VERSION ""

NS_ :

BS_:

BU_: BMS VCU

BO_ 257 BMS_Faults: 8 BMS
 SG_ OverTemp : 1|1@1+ (1,0) [0.0|1.0] ""  VCU
 SG_ OverVoltage : 0|1@1+ (1,0) [0.0|1.0] ""  VCU

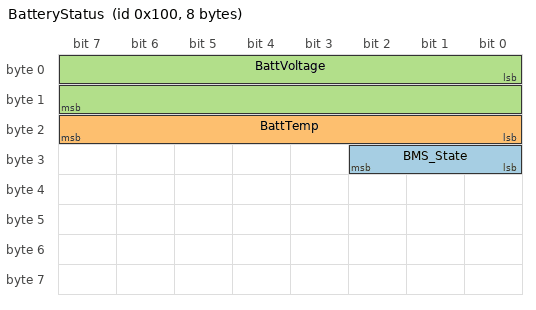
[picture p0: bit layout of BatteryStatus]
BO_ 256 BatteryStatus: 8 BMS
 SG_ BMS_State : 24|3@1+ (1,0) [0.0|7.0] ""  VCU
 SG_ BattTemp : 16|8@1- (1,-40) [-40.0|125.0] "C"  VCU
 SG_ BattVoltage : 0|16@1+ (0.01,0.0) [0.0|65.0] "V"  VCU

CM_ BU_ BMS "Battery Management System";
CM_ BU_ VCU "Vehicle Control Unit";
BA_DEF_ BO_  "GenMsgCycleTime" INT 0 65535;
BA_DEF_DEF_  "GenMsgCycleTime" 0;
BA_ "GenMsgCycleTime" BO_ 257 500;
BA_ "GenMsgCycleTime" BO_ 256 100;
VAL_ 257 OverTemp 0 "Normal" 1 "Alarm" ;
VAL_ 257 OverVoltage 0 "Normal" 1 "Alarm" ;
VAL_ 256 BMS_State 0 "Init" 1 "Standby" 2 "Precharge" 3 "Drive" 4 "Charge" 5 "Fault" ;
